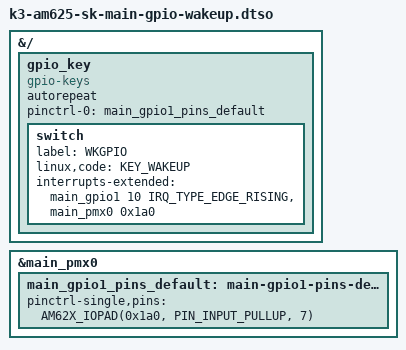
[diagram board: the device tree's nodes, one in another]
// SPDX-License-Identifier: GPL-2.0
/**
 * MAIN GPIO 1_10 on the AM625-SK EVM can be used to wakeup system from deep sleep
 * with the help of this overlay
 *
 * Copyright (C) 2023 Texas Instruments Incorporated - https://www.ti.com/
 */

/dts-v1/;
/plugin/;

#include <dt-bindings/input/input.h>
#include <dt-bindings/gpio/gpio.h>
#include <dt-bindings/interrupt-controller/irq.h>
#include <dt-bindings/interrupt-controller/arm-gic.h>

#include "k3-pinctrl.h"

&{/} {
	gpio_key {
		compatible = "gpio-keys";
		autorepeat;
		pinctrl-names = "default";
		pinctrl-0 = <&main_gpio1_pins_default>;
		switch {
			label = "WKGPIO";
			linux,code = <KEY_WAKEUP>;
			interrupts-extended = <&main_gpio1 10 IRQ_TYPE_EDGE_RISING>,
				<&main_pmx0 0x1a0>;
			interrupt-names = "irq", "wakeup";
		};
	};
};

&main_pmx0 {
	main_gpio1_pins_default: main-gpio1-pins-default {
		pinctrl-single,pins = <
			AM62X_IOPAD(0x1a0, PIN_INPUT_PULLUP, 7) /* (E18) MCASP0_AXR0.EHRPWM1_B */
		>;
	};
};
